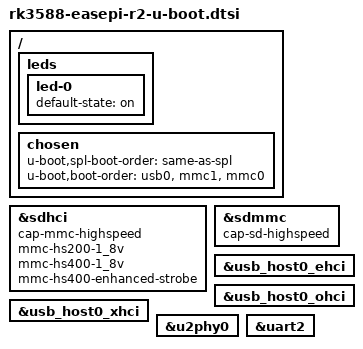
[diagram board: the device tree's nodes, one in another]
// SPDX-License-Identifier: GPL-2.0+
/*
 * (C) Copyright 2021 Rockchip Electronics Co., Ltd
 * (C) Copyright 2023 Akash Gajjar <gajjar04akash@gmail.com>
 * (C) Copyright 2026 EasePi-R2
 */

#include "rk3588-u-boot.dtsi"

/ {
	leds {
		led-0 {
			default-state = "on";
		};
	};

	/* Boot order configuration */
	chosen {
		u-boot,spl-boot-order = "same-as-spl", &usb_host0_xhci, &sdmmc, &sdhci;
		u-boot,boot-order = "usb0", "mmc1", "mmc0";
	};
};

/* eMMC boot support */
&sdhci {
	cap-mmc-highspeed;
	mmc-hs200-1_8v;
	mmc-hs400-1_8v;
	mmc-hs400-enhanced-strobe;
	bootph-pre-ram;
	bootph-some-ram;
	status = "okay";
};

/* TF card (SDMMC) boot support */
&sdmmc {
	cap-sd-highspeed;
	bootph-pre-ram;
	bootph-some-ram;
	status = "okay";
};

/* USB boot support */
&usb_host0_ehci {
	status = "okay";
};

&usb_host0_ohci {
	status = "okay";
};

&usb_host0_xhci {
	status = "okay";
};

&u2phy0 {
	status = "okay";
};

/* Enable U-Boot boot menu */
&uart2 {
	status = "okay";
};
